# ATSAMC21N17A register map
Vendor: Microchip Technology; Series: SAMC21; File version: 0
CPU: CM0+ r0p0, selectable endian, MPU, no FPU, 2 interrupt priority bits
Registers are 32-bit, read-write, reset 0x0 unless marked. A register's access mark holds for its fields unless they carry their own. Offsets are from the block's base; [hi:lo] are bit positions; {n}, {i} and the like mark numbered series; 'fields as' and 'values as' point back to an identical list.

## EVSYS — Event System Interface
Base 0x42000000; register names take the prefix EVSYS_
0x00 CTRLA 8-bit — Control
  [0] SWRST — Software Reset
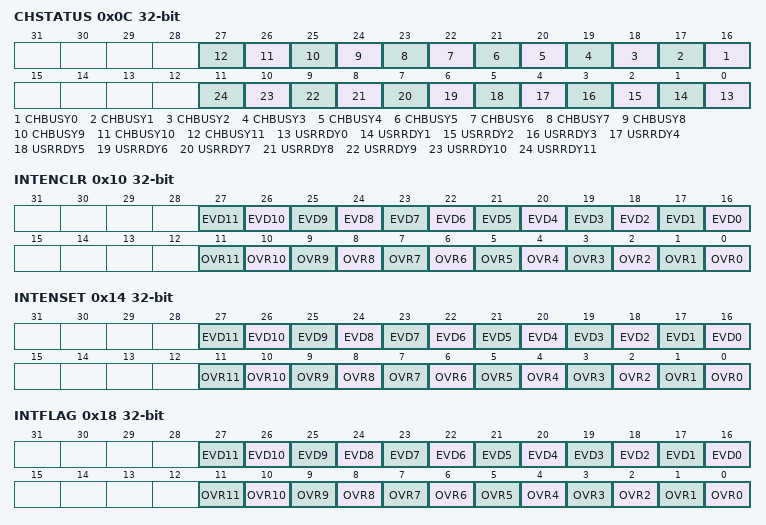
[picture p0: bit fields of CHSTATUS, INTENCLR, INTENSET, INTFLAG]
0x0C CHSTATUS ro — Channel Status
  [n+16] CHBUSY{n} (n=0..11) — Channel {n} Busy
  [n] USRRDY{n} (n=0..11) — Channel {n} User Ready
0x10 INTENCLR — Interrupt Enable Clear
  [n+16] EVD{n} (n=0..11) — Channel {n} Event Detection Interrupt Enable
  [n] OVR{n} (n=0..11) — Channel {n} Overrun Interrupt Enable
0x14 INTENSET — Interrupt Enable Set
  fields as INTENCLR
0x18 INTFLAG — Interrupt Flag Status and Clear
  [n+16] EVD{n} (n=0..11) — Channel {n} Event Detection
  [n] OVR{n} (n=0..11) — Channel {n} Overrun
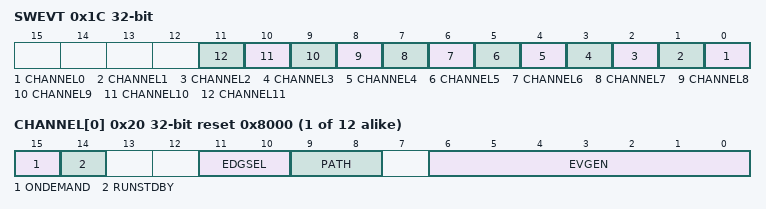
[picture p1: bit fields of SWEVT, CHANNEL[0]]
0x1C SWEVT wo — Software Event
  [n] CHANNEL{n} (n=0..11) — Channel {n} Software Selection
{0x20+4i} CHANNEL[{i}] (i=0..11) reset 0x8000 — Channel n
  [15] ONDEMAND — Generic Clock On Demand
  [14] RUNSTDBY — Run in standby
  [11:10] EDGSEL — Edge Detection Selection
    0=NO_EVT_OUTPUT (No event output when using the resynchronized or synchronous path); 1=RISING_EDGE (Event detection only on the rising edge of the signal from the event generator when using the resynchronized or synchronous path); 2=FALLING_EDGE (Event detection only on the falling edge of the signal from the event generator when using the resynchronized or synchronous path); 3=BOTH_EDGES (Event detection on rising and falling edges of the signal from the event generator when using the resynchronized or synchronous path)
  [9:8] PATH — Path Selection
    0=SYNCHRONOUS (Synchronous path); 1=RESYNCHRONIZED (Resynchronized path); 2=ASYNCHRONOUS (Asynchronous path)
  [6:0] EVGEN — Event Generator Selection
{0x80+4i} USER[{i}] (i=0..49) — User Multiplexer n
  [4:0] CHANNEL — Channel Event Selection

## FREQM — Frequency Meter
Base 0x40002C00; register names take the prefix FREQM_
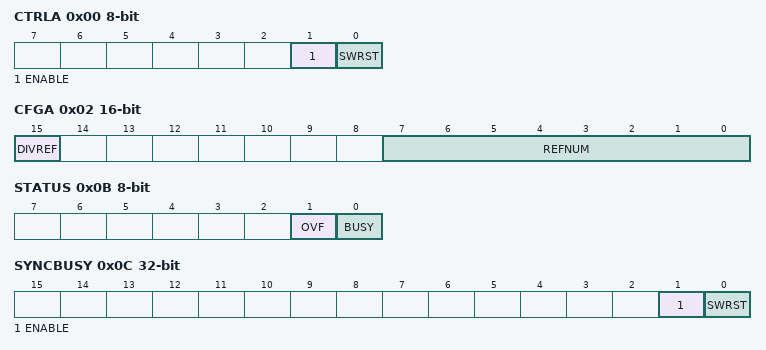
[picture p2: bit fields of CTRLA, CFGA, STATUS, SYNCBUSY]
0x00 CTRLA 8-bit — Control A Register
  [1] ENABLE
  [0] SWRST — Software Reset
0x01 CTRLB 8-bit wo — Control B Register
  [0] START — Start Measurement
0x02 CFGA 16-bit — Config A register
  [15] DIVREF — Divide Reference Clock
  [7:0] REFNUM — Number of Reference Clock Cycles
0x08 INTENCLR 8-bit — Interrupt Enable Clear Register
  [0] DONE — Measurement Done Interrupt Enable
0x09 INTENSET 8-bit — Interrupt Enable Set Register
  [0] DONE — Measurement Done Interrupt Enable
0x0A INTFLAG 8-bit — Interrupt Flag Register
  [0] DONE — Measurement Done
0x0B STATUS 8-bit
  [1] OVF — Sticky Count Value Overflow
  [0] BUSY — FREQM Status
0x0C SYNCBUSY ro — Synchronization Busy Register
  [1] ENABLE
  [0] SWRST — Software Reset
0x10 VALUE ro — Count Value Register
  [23:0] VALUE — Measurement Value

## GCLK — Generic Clock Generator
Base 0x40001C00; register names take the prefix GCLK_
0x00 CTRLA 8-bit — Control
  [0] SWRST — Software Reset
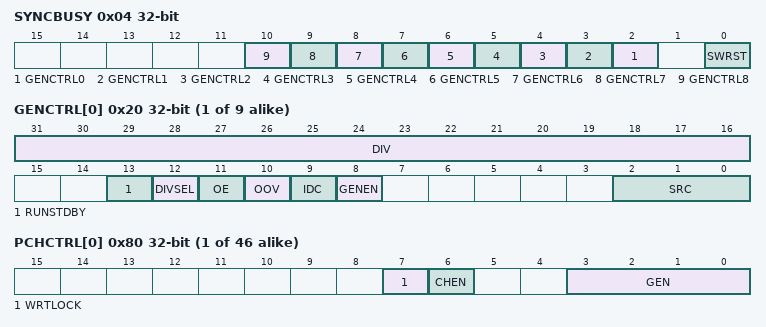
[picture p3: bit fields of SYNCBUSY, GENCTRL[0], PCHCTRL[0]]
0x04 SYNCBUSY ro — Synchronization Busy
  [n+2] GENCTRL{n} (n=0..8) — Generic Clock Generator Control {n} Synchronization Busy bits
    1=GCLK0 (Generic clock generator 0); 2=GCLK1 (Generic clock generator 1); 4=GCLK2 (Generic clock generator 2); 8=GCLK3 (Generic clock generator 3); 16=GCLK4 (Generic clock generator 4); 32=GCLK5 (Generic clock generator 5); 64=GCLK6 (Generic clock generator 6); 128=GCLK7 (Generic clock generator 7); 0x100=GCLK8 (Generic clock generator 8)
  [0] SWRST — Software Reset Synchroniation Busy bit
{0x20+4i} GENCTRL[{i}] (i=0..8) — Generic Clock Generator Control
  [31:16] DIV — Division Factor
  [13] RUNSTDBY — Run in Standby
  [12] DIVSEL — Divide Selection
    0=DIV1 (Divide input directly by divider factor); 1=DIV2 (Divide input by 2^(divider factor+ 1))
  [11] OE — Output Enable
  [10] OOV — Output Off Value
  [9] IDC — Improve Duty Cycle
  [8] GENEN — Generic Clock Generator Enable
  [2:0] SRC — Source Select
    0=XOSC (XOSC oscillator output); 1=GCLKIN (Generator input pad); 2=GCLKGEN1 (Generic clock generator 1 output); 3=OSCULP32K (OSCULP32K oscillator output); 4=OSC32K (OSC32K oscillator output); 5=XOSC32K (XOSC32K oscillator output); 6=OSC48M (OSC48M oscillator output); 7=DPLL96M (DPLL96M output)
{0x80+4i} PCHCTRL[{i}] (i=0..45) — Peripheral Clock Control
  [7] WRTLOCK — Write Lock
  [6] CHEN — Channel Enable
  [3:0] GEN — Generic Clock Generator
    {v}=GCLK{v} (Generic clock generator {v}) (v=0..8)
